# cslr_smc register map
Vendor: Texas Instruments
Peripheral module from a debugger description file (folder c6472).
Registers are 32-bit, access not given, reset 0x0 unless marked. A register's access mark holds for its fields unless they carry their own. Offsets are as the file gives them; lines under a group give offsets from that group; [hi:lo] are bit positions; {n}, {i} and the like mark numbered series; 'fields as' and 'values as' point back to an identical list; <NAME> marks a mode.

## SMC — Shared Memory Controller
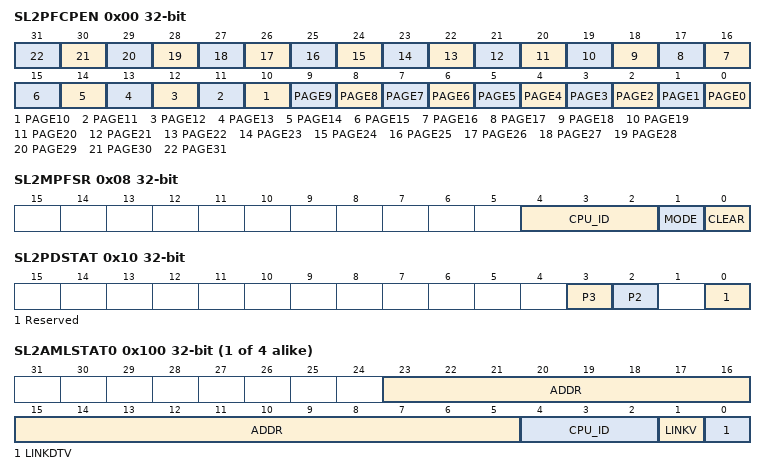
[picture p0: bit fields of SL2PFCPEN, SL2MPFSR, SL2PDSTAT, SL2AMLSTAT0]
0x00 SL2PFCPEN rw — SMC Prefetchable Page Enable Register
  [all] fields
    0=DIS; 1=EN
  [n] PAGE{n} (n=0..31) — PAGE{n} Prefetch Enable
0x04 SL2PFCFLUSH — SMC Prefetchable Buffer Flush Register
  [0] FLUSH wo — Prefetch Buffer Flush
    1=FLUSH
0x08 SL2MPFSR — SMC Memory Protection Fault Status Register
  [4:2] CPU_ID ro
  [1] MODE ro
    0=SECURE; 1=NONSECURE
  [0] CLEAR wo
    1=CLEAR
0x0C SL2MPFAR ro — SMC Memory Protection Fault Address Register
  [31:0] FAULT_ADDRESS
0x10 SL2PDSTAT — SMC Power Down Status
  [3] P3 ro — Physical Page 3
  [2] P2 ro — Physical Page 2
  [0] Reserved — (access N)
{0x100+4i} SL2AMLSTAT{i} (i=0..3) — SMC Atomic access monitor Status
  [23:5] ADDR ro — ADDR IN SMC
  [4:2] CPU_ID ro
  [1] LINKV ro — LINKV=1, ATOMIC LINK IS NOT VALID
  [0] LINKDTV ro — LINKDTV=1, LINK DATA IS VALID
{0x120+4i} SL2AMLDATA{i} ro (i=0..3) — SMC Atomic access data
  [31:0] LINKDATA
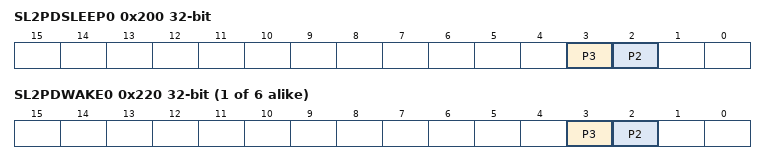
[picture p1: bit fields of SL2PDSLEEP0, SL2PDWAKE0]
0x200 SL2PDSLEEP0 — SMC Power Down Sleep Register
  [3] P3 rw — Physical Page 3
    1=SLEEP
  [2] P2 rw — Physical Page 2
    1=SLEEP
{0x200+4i} SL2PDSLEEP{i} (i=0..5) — SMC Power Down Sleep Register
  fields as SL2PDSLEEP0
{0x220+4i} SL2PDWAKE{i} (i=0..5) — SMC Power Down Wake up Register
  [3] P3 rw — Physical Page 3
    1=WAKE
  [2] P2 rw — Physical Page 2
    1=WAKE
